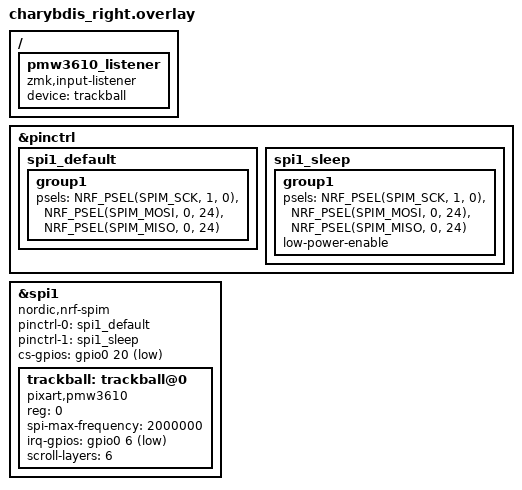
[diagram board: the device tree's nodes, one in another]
&pinctrl {
    spi1_default: spi1_default {
        group1 {
            psels = <NRF_PSEL(SPIM_SCK, 1, 0)>,
                <NRF_PSEL(SPIM_MOSI, 0, 24)>,
                <NRF_PSEL(SPIM_MISO, 0, 24)>;
        };
    };

    spi1_sleep: spi1_sleep {
        group1 {
            psels = <NRF_PSEL(SPIM_SCK, 1, 0)>,
                <NRF_PSEL(SPIM_MOSI, 0, 24)>,
                <NRF_PSEL(SPIM_MISO, 0, 24)>;
            low-power-enable;
        };
    };
};

&spi1 {
    status = "okay";
    compatible = "nordic,nrf-spim";
    pinctrl-0 = <&spi1_default>;
    pinctrl-1 = <&spi1_sleep>;
    pinctrl-names = "default", "sleep";
    cs-gpios = <&gpio0 20 GPIO_ACTIVE_LOW>;

    trackball: trackball@0 {
        status = "okay";
        compatible = "pixart,pmw3610";
        reg = <0>;
        spi-max-frequency = <2000000>;
        irq-gpios = <&gpio0 6 (GPIO_ACTIVE_LOW | GPIO_PULL_UP)>;
        scroll-layers = <6>;
        // snipe-layers = <>;
        // automouse-layer = <>;
    };
};

/ {
  pmw3610_listener {
    compatible = "zmk,input-listener";
    device = <&trackball>;

  };
};
